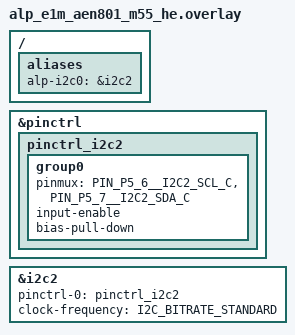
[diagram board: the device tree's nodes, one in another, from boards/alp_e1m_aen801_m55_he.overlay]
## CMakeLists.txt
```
# SPDX-License-Identifier: Apache-2.0

cmake_minimum_required(VERSION 3.20)

# board.yaml -> build/generated/alp.conf at configure time, layered
# over prj.conf via EXTRA_CONF_FILE.  Both the emit and the append
# MUST happen before find_package(Zephyr) -- cmake/alp.cmake documents
# why, and the ALP_SDK_ROOT contract a copied-out project relies on.
if(DEFINED ENV{ALP_SDK_ROOT})
    set(ALP_SDK_ROOT $ENV{ALP_SDK_ROOT})
else()
    get_filename_component(ALP_SDK_ROOT ${CMAKE_CURRENT_SOURCE_DIR}/../../.. ABSOLUTE)
endif()
include(${ALP_SDK_ROOT}/cmake/alp.cmake)

alp_sdk_zephyr_conf(m55_he)

find_package(Zephyr REQUIRED HINTS $ENV{ZEPHYR_BASE})
project(aen_eeprom_manifest LANGUAGES C)

target_sources(app PRIVATE src/main.c)
```

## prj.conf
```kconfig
# SPDX-License-Identifier: Apache-2.0
CONFIG_PRINTK=y
CONFIG_LOG=y

# Link the app at the HE MRAM app partition (0x80010000) so its vector table
# matches the ATOC load address (app-zephyr-he.json mramAddress=0x80010000).
# FLASH_BASE is the full MRAM (0x80000000); without this 0x10000 offset the
# image links at 0x80000000 and the SES boots it 64 KB low -> fault/no-boot.
# Same mechanism as the aen-cc3501e-* examples (see their prj.conf) -- this
# app is a flashed SES/slot0 target, not an ITCM RAM-run.
CONFIG_FLASH_LOAD_OFFSET=0x10000
```

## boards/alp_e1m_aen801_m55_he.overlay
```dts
/*
 * Copyright (c) 2026 Alp Lab AB
 * SPDX-License-Identifier: Apache-2.0
 *
 * Wire the on-module 24C128 EEPROM bus for the manifest read on the E1M-AEN801
 * (M55-HE).  The EEPROM's interface is selected by bridge/DNP resistors onto SoC
 * I2C2 (DesignWare master, upstream i2c_dw), pins P5_6 SCL_C / P5_7 SDA_C -- NOT
 * the slave-only LPI2C0.  Map portable bus 0 (alp-i2c0) -> &i2c2.
 */
#include <zephyr/dt-bindings/pinctrl/alif-ensemble-pinctrl.h>
#include <zephyr/dt-bindings/i2c/i2c.h>

&pinctrl {
	pinctrl_i2c2: pinctrl_i2c2 {
		group0 {
			pinmux = <PIN_P5_6__I2C2_SCL_C>, <PIN_P5_7__I2C2_SDA_C>;
			/* I2C pad config -- BENCH-VALIDATED on the E8 (2026-06-15) and
			 * matching Alif's own reference i2c pinctrl (sdk-alif
			 * common/ensemble-pinctrl.dtsi: read-enable=1 +
			 * driver-state-control=2):
			 *   input-enable    -> pad REN bit: the i2c_dw controller MUST be
			 *                      able to SENSE SDA/SCL or it reads every
			 *                      address as a NACK (no ACK detect). Without
			 *                      this the EEPROM never responds.
			 *   bias-pull-down  -> upstream pinctrl_soc.h encodes the pad
			 *                      driver-state-control (DSC) field as DSC=2
			 *                      from bias-pull-down -- which is exactly the
			 *                      value Alif's reference uses for I2C. (DSC=1
			 *                      via bias-pull-up does NOT work -> dead bus;
			 *                      the upstream binding's pull naming is
			 *                      effectively inverted vs the Alif pad HW.)
			 * Do NOT "correct" bias-pull-down to bias-pull-up.
			 */
			input-enable;
			bias-pull-down;
		};
	};
};

&i2c2 {
	status = "okay";
	pinctrl-0 = <&pinctrl_i2c2>;
	pinctrl-names = "default";
	/* 100 kHz: bench-validated; the on-module bus has no fast-mode margin
	 * unless external pull-ups are stuffed. */
	clock-frequency = <I2C_BITRATE_STANDARD>;
};

/ {
	aliases {
		alp-i2c0 = &i2c2;
	};
};
```

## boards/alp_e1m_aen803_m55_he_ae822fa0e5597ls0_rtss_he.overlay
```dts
/*
 * Copyright (c) 2026 Alp Lab AB
 * SPDX-License-Identifier: Apache-2.0
 *
 * Wire the on-module 24C128 EEPROM bus for the manifest read on the E1M-AEN803
 * (M55-HE).  The EEPROM's interface is selected by bridge/DNP resistors onto SoC
 * I2C2 (DesignWare master, upstream i2c_dw), pins P5_6 SCL_C / P5_7 SDA_C -- NOT
 * the slave-only LPI2C0.  Map portable bus 0 (alp-i2c0) -> &i2c2.
 */
#include <zephyr/dt-bindings/pinctrl/alif-ensemble-pinctrl.h>
#include <zephyr/dt-bindings/i2c/i2c.h>

&pinctrl {
	pinctrl_i2c2: pinctrl_i2c2 {
		group0 {
			pinmux = <PIN_P5_6__I2C2_SCL_C>, <PIN_P5_7__I2C2_SDA_C>;
			/* I2C pad config -- BENCH-VALIDATED on the E8 (2026-06-15) and
			 * matching Alif's own reference i2c pinctrl (sdk-alif
			 * common/ensemble-pinctrl.dtsi: read-enable=1 +
			 * driver-state-control=2):
			 *   input-enable    -> pad REN bit: the i2c_dw controller MUST be
			 *                      able to SENSE SDA/SCL or it reads every
			 *                      address as a NACK (no ACK detect). Without
			 *                      this the EEPROM never responds.
			 *   bias-pull-down  -> upstream pinctrl_soc.h encodes the pad
			 *                      driver-state-control (DSC) field as DSC=2
			 *                      from bias-pull-down, a REAL pull-down --
			 *                      exactly Alif's reference value for I2C, and
			 *                      NOT an inverted encoding: pinctrl_soc.h's
			 *                      ALIF_PINCTRL_BIAS_CFG() macro (lines 44-48)
			 *                      maps bias-pull-up -> DSC=1 and
			 *                      bias-pull-down -> DSC=2 unconditionally,
			 *                      matching the field comment at line 24.  A
			 *                      real pull-down is harmless here because the
			 *                      EVK carrier's R137/R144 pull-ups are stuffed
			 *                      on this bus and dominate a weak internal
			 *                      one.  Switching to bias-pull-up was earlier
			 *                      reported to give a dead bus, blamed on that
			 *                      (nonexistent) inversion -- the dead-bus
			 *                      report is therefore UNCONFIRMED, not
			 *                      disproven, absent a fresh bench trial; it is
			 *                      not evidence either way.
			 * Do NOT "correct" bias-pull-down to bias-pull-up: it is the
			 * bench-validated, correct-as-emitted value regardless of which
			 * reading is right (alp-sdk#2046).
			 */
			input-enable;
			bias-pull-down;
		};
	};
};

&i2c2 {
	status = "okay";
	pinctrl-0 = <&pinctrl_i2c2>;
	pinctrl-names = "default";
	/* 100 kHz: bench-validated; the on-module bus has no fast-mode margin
	 * unless external pull-ups are stuffed. */
	clock-frequency = <I2C_BITRATE_STANDARD>;
};

/ {
	aliases {
		alp-i2c0 = &i2c2;
	};
};
```

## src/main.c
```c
/*
 * Copyright 2026 Alp Lab AB
 * SPDX-License-Identifier: Apache-2.0
 *
 * aen-eeprom-manifest -- read + decode the 128-byte Alp hardware-info
 * manifest from the on-module 24C128 EEPROM on the E1M-AEN (Alif Ensemble) SoM.
 *
 * The src is the AEN sibling of examples/v2n/v2n-eeprom-manifest-dump -- the
 * read goes through the SoM-portable <alp/...> API, so the only AEN-specific fact
 * is the bus: the EEPROM's interface is selected by bridge/DNP resistors onto
 * the **SoC I2C2** DesignWare master bus (P5_6 SCL_C / P5_7 SDA_C), surfaced as
 * portable bus 0 -- NOT BRD_I2C (SoC I2C0, which carries the RTC/TMP/OPTIGA
 * instead -- see examples/aen/aen-secure-element-sign).  I2C2 is driven by
 * upstream Zephyr's i2c_dw (full master read+write), per ADR 0017 (alp-sdk over
 * the vendor SDK -- Tier-1 upstream-native).
 *
 * Run this after receiving a module from the line: if the manifest is malformed,
 * the firmware build's expected-SKU assertion will halt the boot path later.
 */

#include <stdio.h>
#include <string.h>

#include <zephyr/kernel.h>

#include "alp/peripheral.h"
#include "alp/chips/eeprom_24c128.h"
#include "alp/hw_info.h"

/* CRC-32 ISO-3309 (poly 0xEDB88320, init/xor-out 0xFFFFFFFF) -- matches
 * zlib.crc32, the algorithm scripts/program_eeprom.py uses. Table-free
 * bit-at-a-time form: the manifest is <128 bytes, so a lookup table would
 * only add flash footprint without a measurable speed win here. */
static uint32_t crc32_iso3309(const uint8_t *buf, size_t len)
{
	uint32_t crc = 0xFFFFFFFFu;
	for (size_t i = 0; i < len; ++i) {
		crc ^= (uint32_t)buf[i];
		for (unsigned b = 0; b < 8; ++b) {
			uint32_t mask = (uint32_t)-(int32_t)(crc & 1u);
			crc           = (crc >> 1) ^ (0xEDB88320u & mask);
		}
	}
	return ~crc;
}

/* xxd-style 16-byte-per-line hex dump. */
static void hex_dump(const uint8_t *buf, size_t len)
{
	for (size_t off = 0; off < len; off += 16u) {
		printf("  %04zx  ", off);
		for (size_t i = 0; i < 16u; ++i) {
			if (off + i < len) {
				printf("%02x ", buf[off + i]);
			} else {
				printf("   ");
			}
		}
		printf(" |");
		for (size_t i = 0; i < 16u; ++i) {
			if (off + i < len) {
				uint8_t c = buf[off + i];
				printf("%c", (c >= 0x20 && c < 0x7f) ? c : '.');
			}
		}
		printf("|\n");
	}
}

int main(void)
{
	printf("[manifest] aen-eeprom-manifest\n");

	/* The 24C128 is on portable bus 0 -> SoC I2C2 (the board overlay aliases
	 * alp-i2c0 to &i2c2 + supplies pinctrl_i2c2 on P5_6/P5_7).  0x50 is the
	 * 24C128's standard 7-bit address. */
	alp_i2c_t *bus = alp_i2c_open(&(alp_i2c_config_t){
	    .bus_id     = 0u,
	    .bitrate_hz = 100000u,
	});
	/* Unlike the AEN Trust M probe (which SKIPs on ALP_ERR_NOT_READY because
	 * OPTIGA population on BRD_I2C varies by assembly), I2C2 backs the manifest
	 * EEPROM that every E1M-AEN801 module ships with populated -- so any
	 * open failure here is a real fault, not an expected-absent-part SKIP. */
	if (bus == NULL) {
		printf("[manifest] alp_i2c_open failed: err=%d\n", (int)alp_last_error());
		printf("RESULT FAIL: alp_i2c_open -> NULL, err=%d\n", (int)alp_last_error());
		return 0;
	}

	eeprom_24c128_t ee;
	alp_status_t    s = eeprom_24c128_init(&ee, bus, 0x50u);
	if (s != ALP_OK) {
		printf("[manifest] eeprom_24c128_init -> %d "
		       "(EEPROM populated?  bridge/DNP selecting I2C2?  bus right?)\n",
		       (int)s);
		printf("RESULT FAIL: eeprom_24c128_init -> %d\n", (int)s);
		alp_i2c_close(bus);
		return 0;
	}

	/* One shot: the EEPROM auto-increments its address pointer, so the
	 * underlying I2C op is a single write-then-read (repeated-START). */
	uint8_t raw[128];
	s = eeprom_24c128_read(&ee, /* offset */ 0x0000u, raw, sizeof(raw));
	if (s != ALP_OK) {
		printf("[manifest] eeprom_24c128_read -> %d (bus error?)\n", (int)s);
		printf("RESULT FAIL: eeprom_24c128_read -> %d\n", (int)s);
		eeprom_24c128_deinit(&ee);
		alp_i2c_close(bus);
		return 0;
	}

	printf("[manifest] raw bytes:\n");
	hex_dump(raw, sizeof(raw));

	/* memcpy, not a cast -- raw is a uint8_t[] (alignment 1);
	 * alp_hw_info_eeprom_t needs alignment 4 for its uint32_t
	 * magic/schema_version/crc32 and uint16_t mfg_year. Reading through a
	 * cast pointer is the same misaligned-access bug already fixed on the
	 * Secure Data Page path (see alp_secure_page_mirror_classify()'s doc
	 * comment in include/alp/hw_info.h) and left unswept here. */
	alp_hw_info_eeprom_t manifest;
	memcpy(&manifest, raw, sizeof(manifest));
	const alp_hw_info_eeprom_t *m = &manifest;

	/* Each field check's OK/FAIL folds into `magic_ok` / `schema_ok` /
	 * `crc_ok` below (crc_ok is set where it's computed, further down) --
	 * those three are what the RESULT verdict at the end of main() gates
	 * on, so a malformed or unprogrammed manifest cannot read as PASS. */
	bool magic_ok = (m->magic == ALP_HW_INFO_MAGIC);
	printf("\n[manifest] magic         = 0x%08x", m->magic);
	if (magic_ok) {
		printf("  (OK -- ASCII 'ALPH')\n");
	} else {
		printf("  (FAIL -- expected 0x%08x; module not programmed?)\n", ALP_HW_INFO_MAGIC);
	}

	bool schema_ok = (m->schema_version == ALP_HW_INFO_SCHEMA_VERSION);
	printf("[manifest] schema_version= %u", (unsigned)m->schema_version);
	printf(schema_ok ? "  (OK)\n" : "  (FAIL)\n");

	printf("[manifest] family        = %.*s\n", ALP_HW_INFO_FAMILY_LEN, m->family);
	printf("[manifest] sku           = %.*s\n", ALP_HW_INFO_SKU_LEN, m->sku);
	printf("[manifest] hw_rev        = %.*s\n", ALP_HW_INFO_HW_REV_LEN, m->hw_rev);
	printf("[manifest] serial        = %.*s\n", ALP_HW_INFO_SERIAL_LEN, m->serial);
	printf("[manifest] mfg date      = %04u-%02u-%02u\n",
	       (unsigned)m->mfg_year,
	       (unsigned)m->mfg_month,
	       (unsigned)m->mfg_day);

	/* The CRC is stored as the manifest's last field and covers every byte
	 * before it -- excluding the CRC field itself, since it can't cover its
	 * own value. A mismatch here means either a partial/interrupted EEPROM
	 * program or a bit-rot/corruption event, distinct from "never programmed"
	 * (which the magic check above already catches). */
	const size_t crc_covered_len = sizeof(*m) - sizeof(m->crc32);
	uint32_t     calc            = crc32_iso3309(raw, crc_covered_len);
	bool         crc_ok          = (calc == m->crc32);
	printf("[manifest] crc32         = 0x%08x (stored) vs 0x%08x (computed)", m->crc32, calc);
	printf(crc_ok ? "  (OK)\n" : "  (FAIL -- partial program or corruption)\n");

	/* --- second device-select header (0x58) --------------------------------
	 * This is the SAME physical N24S128 part answering a second, read-only
	 * identity space -- not a second chip on the bus.  Its `1011` header sits
	 * at ctx's array address (0x50) + EEPROM_24C128_ALT_ADDR_OFFSET (0x08) =
	 * 0x58, and exposes four objects instead of the 16 KB array:
	 * Secure Data Page, Unique ID, Lock Status, and Device Configuration
	 * Register. eeprom_24c128_read_identity() reads all four in one call.
	 *
	 * This example deliberately never calls eeprom_24c128_write() -- here or
	 * anywhere else: a stray write at selector 0x06 lands in the Device
	 * Configuration Register.  Per the N24S128 datasheet Table 9 that
	 * register is `b7 b6 b5 = A2 A1 A0` and `b1 = SWP` -- the device-address
	 * bits are the HIGH three, which is why the bench-measured 0x1D
	 * (0b0001_1101) reads as address 000 with SWP clear.  Writing that
	 * register would move the EEPROM off 0x50, and its SWP bit permanently
	 * write-protects the array, the Secure Data Page, and the register
	 * together -- there is no way back from that on this part, so this
	 * read-only example won't go near it. */
	eeprom_24c128_identity_t id;
	s = eeprom_24c128_read_identity(&ee, &id);
	if (s != ALP_OK) {
		/* Only a NULL out/ctx or an uninitialised ctx return non-OK here -- a
		 * NACK from the silicon itself still returns ALP_OK with the
		 * per-field _valid flags clear (handled below). So landing in this
		 * branch means a programming error in this example, not a hardware
		 * condition, and it is deliberately kept out of the RESULT verdict:
		 * it can't happen without a code bug, unlike the identity objects'
		 * _valid flags below, which legitimately vary by populated part. */
		printf("[manifest] eeprom_24c128_read_identity -> %d (programming error, not "
		       "a hardware condition)\n",
		       (int)s);
	} else {
		printf("\n[manifest] second device-select header (0x58, N24S128 only):\n");

		/* A _valid flag reading false here, with read_identity() itself still
		 * ALP_OK, is NOT a failure -- it is the expected, documented result on
		 * a board populated with the footprint-compatible M24128-BFMH6TG
		 * alternate part, which has no second device-select header to answer
		 * at all. None of the four checks below feed the RESULT verdict at
		 * the end of main(): an absent second header is an absent capability,
		 * not a fault. */
		if (id.secure_page_valid) {
			printf("[manifest]   Secure Data Page (%u bytes, erased = all 0xff):\n",
			       (unsigned)sizeof(id.secure_page));
			hex_dump(id.secure_page, sizeof(id.secure_page));
		} else {
			printf("[manifest]   Secure Data Page        : NACK (expected on the "
			       "M24128-BFMH6TG alternate -- no second header to answer)\n");
		}

		if (id.unique_id_valid) {
			/* Factory-set, but NOT uniform-random: bytes 8..14 are a
			 * printable ASCII lot code (bench-observed "7321261" on the
			 * 2026W36 unit) -- callers must not treat this as an entropy
			 * source. */
			printf("[manifest]   Unique ID (factory-set, not uniform-random -- a "
			       "trailing run is a printable lot code):\n");
			hex_dump(id.unique_id, sizeof(id.unique_id));
		} else {
			printf("[manifest]   Unique ID               : NACK (expected on the "
			       "M24128-BFMH6TG alternate -- no second header to answer)\n");
		}

		if (id.lock_valid) {
			printf("[manifest]   Secure Page Lock Status : 0x%02x (%s)\n",
			       (unsigned)id.lock_status,
			       id.secure_page_locked ? "LOCKED (permanent)" : "UNLOCKED");
		} else {
			printf("[manifest]   Secure Page Lock Status : NACK (expected on the "
			       "M24128-BFMH6TG alternate -- no second header to answer)\n");
		}

		if (id.device_config_valid) {
			printf("[manifest]   Device Configuration Reg: 0x%02x\n", (unsigned)id.device_config);
		} else {
			printf("[manifest]   Device Configuration Reg: NACK (expected on the "
			       "M24128-BFMH6TG alternate -- no second header to answer)\n");
		}
	}

	/* Production apps call alp_hw_info_read() instead of decoding by hand;
	 * that path is enabled by setting CONFIG_ALP_SDK_HW_INFO_EEPROM_I2C_BUS_ID
	 * >= 0 in prj.conf (0 selects `e1m_i2c0`, agreeing with the EEPROM's
	 * `e1m_i2c0` -> SoC I2C2 placement in
	 * metadata/e1m_modules/E1M-AEN801.yaml's `i2c_devices:` block). This
	 * example leaves the Kconfig at its `-1` (disabled) default and
	 * decodes the manifest by hand instead, so alp_hw_info_read() is not
	 * called above. */

	eeprom_24c128_deinit(&ee);
	alp_i2c_close(bus);
	printf("[manifest] done\n");

	/* RESULT verdict -- gated on the three field checks actually decoded
	 * above, not on merely reaching this line: a torn/unprogrammed EEPROM
	 * still lets the I2C read succeed (I2C doesn't know the payload is
	 * garbage), so only magic_ok/schema_ok/crc_ok tell us the manifest is
	 * real. */
	if (magic_ok && schema_ok && crc_ok) {
		printf("RESULT PASS: manifest magic/schema/crc32 all OK\n");
	} else {
		printf("RESULT FAIL: manifest %s%s%s\n",
		       magic_ok ? "" : "magic mismatch ",
		       schema_ok ? "" : "schema_version mismatch ",
		       crc_ok ? "" : "crc32 mismatch");
	}
	return 0;
}
```
